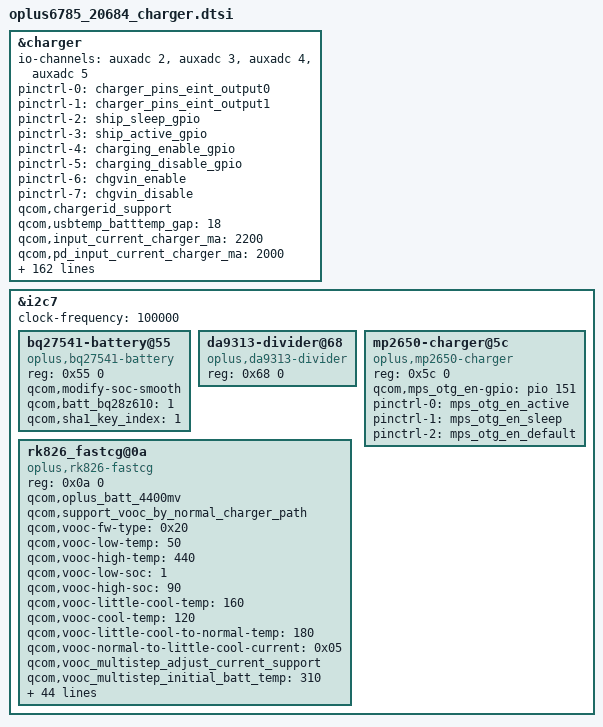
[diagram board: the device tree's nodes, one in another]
&charger {
	io-channels = <&auxadc 2>,
		      <&auxadc 3>,
		      <&auxadc 4>,
		      <&auxadc 5>;
	io-channel-names = "thermistor-ch2_usb_ntc_l",
			   "thermistor-ch3_usb_ntc_r",
			   "thermistor-ch4_charger_ntc",
			   "thermistor-ch5_flashlight_ntc";

	pinctrl-names = "charger_gpio_as_output_low", "charger_gpio_as_output_high", "ship_sleep", "ship_active", "dischg_disable", "dischg_enable", "chgvin_enable", "chgvin_disable";
	pinctrl-0 = <&charger_pins_eint_output0>;
	pinctrl-1 = <&charger_pins_eint_output1>;
	pinctrl-2 = <&ship_sleep_gpio>;
	pinctrl-3 = <&ship_active_gpio>;
	pinctrl-4 = <&charging_enable_gpio>;
	pinctrl-5 = <&charging_disable_gpio>;
	//pinctrl-5 = <&shortc_active_gpio>;
	pinctrl-6 = <&chgvin_enable>;
	pinctrl-7 = <&chgvin_disable>;
	//qcom,hv_flashled_support;
	//for oplus chg framework:
	qcom,chargerid_support;
	qcom,usbtemp_batttemp_gap = <18>;
	qcom,input_current_charger_ma = <2200>;
	qcom,pd_input_current_charger_ma = <2000>;
	qcom,qc_input_current_charger_ma = <2000>;
	qcom,input_current_usb_ma = <500>;
	qcom,input_current_cdp_ma = <1500>;
	qcom,input_current_led_ma = <1200>;
	qcom,input_current_led_ma_forcmcc = <500>;
	qcom,input_current_camera_ma = <2000>;
	qcom,input_current_calling_ma = <1500>;
	qcom,input_current_led_ma_high = <500>;
	qcom,input_current_led_ma_limit_high = <1200>;
	qcom,input_current_led_ma_warm = <1500>;
	qcom,input_current_led_ma_normal = <2000>;

	qcom,led_warm_bat_decidegc = <350>;
	qcom,led_limit_high_bat_decidegc = <370>;

	qcom,input_current_vooc_led_ma_high = <1200>;
	qcom,input_current_vooc_led_ma_warm = <1800>;
	qcom,input_current_vooc_led_ma_normal = <3600>;
	qcom,input_current_vooc_ma_normal = <3600>;
	qcom,vooc_temp_bat_normal_decidegc = <350>;
	qcom,input_current_vooc_ma_warm = <3200>;
	qcom,vooc_temp_bat_warm_decidegc = <370>;
	qcom,input_current_vooc_ma_high = <2200>;
	qcom,led_high_bat_decidegc = <440>;
	qcom,vooc_temp_bat_hot_decidegc = <440>;

	qcom,charger_current_vooc_ma_normal = <1800>;

	qcom,overtemp_bat_decidegc = <350>;
	qcom,iterm_disabled = <0>;
	sw_full_count = <25>;
	qcom,iterm_ma = <115>;
	qcom,recharge-mv = <105>;

	qcom,batt_capacity_mah = <4500>; /*typical capacity*/
	//qcom,batt_capacity_mah = <3900>; /*rated capacity*/

	qcom,removed_bat_decidegc = <190>;  /* < -19C */

	qcom,cold_bat_decidegc = <20>;  /* -3C ~ 0C */
	qcom,temp_cold_vfloat_mv = <3980>;
	qcom,temp_cold_fastchg_current_ma = <300>;

	qcom,little_cold_bat_decidegc = <0>;	/* 0C ~ 5C */
	qcom,temp_little_cold_vfloat_mv = <4435>;
	qcom,temp_little_cold_fastchg_current_ma_high = <950>;
	qcom,temp_little_cold_fastchg_current_ma_low = <950>;
	qcom,temp_little_cold_fastchg_current_ma = <950>;
	qcom,pd_temp_little_cold_fastchg_current_ma_high = <2000>;
	qcom,pd_temp_little_cold_fastchg_current_ma_low = <1400>;
	qcom,qc_temp_little_cold_fastchg_current_ma_high = <2000>;
	qcom,qc_temp_little_cold_fastchg_current_ma_low = <1400>;

	qcom,cool_bat_decidegc = <50>;	/* 5C ~ 12C */
	qcom,temp_cool_vfloat_mv = <4435>;
	qcom,temp_cool_fastchg_current_ma_high = <1000>;
	qcom,temp_cool_fastchg_current_ma_low = <1100>;
	qcom,pd_temp_cool_fastchg_current_ma_high = <2000>;
	qcom,qc_temp_cool_fastchg_current_ma_high = <2000>;
	qcom,qc_temp_cool_fastchg_current_ma_low = <2000>;

	qcom,little_cool_bat_decidegc = <120>;	/* 12C ~ 16C */
	qcom,temp_little_cool_vfloat_mv = <4435>;
	qcom,temp_little_cool_fastchg_current_ma = <1000>;
	qcom,pd_temp_little_cool_fastchg_current_ma = <2000>;
	qcom,qc_temp_little_cool_fastchg_current_ma = <2000>;

	qcom,normal_bat_decidegc = <160>;	/* 16C ~ 45C */
	qcom,temp_normal_fastchg_current_ma = <1000>;
	qcom,temp_normal_vfloat_mv = <4435>;
	qcom,pd_temp_normal_fastchg_current_ma = <2000>;
	qcom,qc_temp_normal_fastchg_current_ma = <2000>;

	qcom,warm_bat_decidegc = <440>;		/* 45C ~ 53C */ /*8pin Bat Vooc project need add 3 degree C*/

	qcom,temp_warm_vfloat_mv = <4120>;
	qcom,temp_warm_fastchg_current_ma = <550>;
	qcom,pd_temp_warm_fastchg_current_ma = <600>;
	qcom,qc_temp_warm_fastchg_current_ma = <600>;
	qcom,temp_warm_fastchg_current_ma_led_on = <250>;

	qcom,hot_bat_decidegc = <530>;  /* > 53C */

	qcom,non_standard_vfloat_mv = <3980>;
	qcom,non_standard_fastchg_current_ma = <512>;

	qcom,short_c_bat_cv_mv = <4330>;
	qcom,short_c_bat_vfloat_mv = <3800>;
	qcom,short_c_bat_fastchg_current_ma = <512>;
	qcom,short_c_bat_vfloat_sw_limit = <3750>;

	qcom,cold_vfloat_sw_limit = <3930>;
	qcom,little_cold_vfloat_sw_limit = <4385>;
	qcom,cool_vfloat_sw_limit = <4385>;
	qcom,little_cool_vfloat_sw_limit = <4385>;
	qcom,normal_vfloat_sw_limit = <4385>;
	qcom,warm_vfloat_sw_limit = <4080>;
	qcom,non_standard_vfloat_sw_limit = <3930>;

	qcom,max_chg_time_sec = <60624>;
	qcom,charger_hv_thr = <9900>;
	qcom,charger_recv_thr = <9500>;
	qcom,charger_lv_thr = <3400>;
	qcom,vbatt_full_thr = <4400>;
	qcom,vbatt_hv_thr = <4550>;

	qcom,vfloat_step_mv = <8>;
	qcom,non_standard_vfloat_over_sw_limit = <3980>;
	qcom,cold_vfloat_over_sw_limit = <3980>;
	qcom,little_cold_vfloat_over_sw_limit = <4440>;
	qcom,cool_vfloat_over_sw_limit = <4440>;
	qcom,little_cool_vfloat_over_sw_limit = <4440>;
	qcom,normal_vfloat_over_sw_limit = <4440>;
	qcom,warm_vfloat_over_sw_limit = <4135>;

	qcom,vbatt_power_off = <3300>;
	qcom,vbatt_soc_1 = <3310>;
	qcom,vooc_project = <3>;
	qcom,vbatt_num = <2>;
	qcom,new_ui_warning_support;
	qcom,ffc_support;
	qcom,dual_ffc;
	recharge_after_full;

	qcom,normal_vterm_hw_inc = <18>;
	qcom,non_normal_vterm_hw_inc = <18>;

	qcom,ff1_normal_fastchg_ma = <550>;
	qcom,ff1_warm_fastchg_ma = <550>;
	qcom,ffc2_normal_fastchg_ma = <350>;/*12C~35c*/
	qcom,ffc2_temp_warm_decidegc = <350>;
	qcom,ffc2_warm_fastchg_ma = <350>;/*35C~40c*/
	qcom,ffc2_temp_high_decidegc = <400>;
	qcom,ffc2_temp_low_decidegc = <120>;
	qcom,ff1_exit_step_ma = <150>;
	qcom,ff1_warm_exit_step_ma = <150>;
	qcom,ffc2_exit_step_ma = <150>;
	qcom,ffc2_warm_exit_step_ma = <150>;

	qcom,ffc_normal_vfloat_sw_limit = <4455>;
	qcom,ffc_temp_normal_vfloat_mv = <4500>;
	qcom,ffc_normal_vfloat_over_sw_limit = <4500>;
	qcom,ffc_warm_vfloat_sw_limit = <4450>;
	qcom,ffc_temp_warm_vfloat_mv = <4500>;
	qcom,ffc_warm_vfloat_over_sw_limit = <4500>;

	qcom,ffc2_normal_vfloat_sw_limit = <4445>;
	qcom,ffc2_temp_normal_vfloat_mv = <4500>;
	qcom,ffc2_normal_vfloat_over_sw_limit = <4500>;
	qcom,ffc2_warm_vfloat_sw_limit = <4440>;
	qcom,ffc2_temp_warm_vfloat_mv = <4500>;
	qcom,ffc2_warm_vfloat_over_sw_limit = <4500>;

	qcom,default_iterm_ma = <115>;
	qcom,default_temp_normal_fastchg_current_ma = <2200>;
	qcom,default_normal_vfloat_sw_limit = <4385>;
	qcom,default_temp_normal_vfloat_mv = <4435>;
	qcom,default_normal_vfloat_over_sw_limit = <4440>;
	qcom,default_temp_little_cool_fastchg_current_ma = <1100>;
	qcom,default_little_cool_vfloat_sw_limit = <4385>;
	qcom,default_temp_little_cool_vfloat_mv = <4435>;
	qcom,default_little_cool_vfloat_over_sw_limit = <4445>;
	//qcom,suspend_after_full;
	qcom,check_batt_full_by_sw;
	qcom,external_gauge;
	qcom,chg_ctrl_by_calling;
	qcom,chg_ctrl_by_lcd;
	qcom,chg_ctrl_by_vooc;
	qcom,chg_ctrl_by_camera;
	qcom,sw_vfloat_over_protect_enable;

	//for PD9V or QC9V
	qcom,vbatt_pdqc_to_5v_thr = <4100>;
	qcom,vbatt_pdqc_to_9v_thr = <4000>;

	//GPIO config:
	qcom,chargerid_switch-gpio = <&pio 195 0x00>;
	qcom,ship-gpio = <&pio 26 0x00>;
	qcom,dischg-gpio = <&pio 13 0x00>;
	//qcom,shortc-gpio = <&pio 148 0x00>;
	qcom,chgvin = <&pio 127 0x00>;
};

&i2c7 {
	status = "okay";
	clock-frequency = <100000>;
	bq27541-battery@55 {
		status = "okay";
		compatible = "oplus,bq27541-battery";
		reg = <0x55 0>;
		qcom,modify-soc-smooth;
		qcom,batt_bq28z610 = <1>;
		qcom,sha1_key_index = <1>;
		//qcom,bq28z610_need_balancing;
	};

	da9313-divider@68 {
		status = "okay";
		compatible = "oplus,da9313-divider";
		reg = <0x68 0>;
	};

	mp2650-charger@5c {
		status = "okay";
		compatible = "oplus,mp2650-charger";
		reg = <0x5c 0>;

		qcom,mps_otg_en-gpio = <&pio 151 0x00>;
		pinctrl-names = "mps_otg_en_active", "mps_otg_en_sleep", "mps_otg_en_default";
		pinctrl-0 = <&mps_otg_en_active>;
		pinctrl-1 = <&mps_otg_en_sleep>;
		pinctrl-2 = <&mps_otg_en_default>;
	};

	rk826_fastcg@0a{
		status = "okay";
		compatible = "oplus,rk826-fastcg";
		reg = <0x0a 0>;
		qcom,oplus_batt_4400mv;
		qcom,support_vooc_by_normal_charger_path;
		//qcom,vooc_fw_update_newmethod;
		qcom,vooc-fw-type = <0x20>;
		//qcom,vooc_reply_mcu_bits = <7>;
		qcom,vooc-low-temp = <50>;
		qcom,vooc-high-temp = <440>;
		qcom,vooc-low-soc = <1>;
		qcom,vooc-high-soc = <90>;
		qcom,vooc-little-cool-temp = <160>;
		qcom,vooc-cool-temp = <120>;
		qcom,vooc-little-cool-to-normal-temp = <180>;
		qcom,vooc-normal-to-little-cool-current = <0x05>;//5A

		qcom,vooc_multistep_adjust_current_support;
		qcom,vooc_multistep_initial_batt_temp = <310>;
		qcom,vooc_strategy_normal_current = <0x06>;
		qcom,vooc_batt_over_high_temp = <440>;
		qcom,vooc_batt_over_low_temp = <45>;
		qcom,vooc_over_high_or_low_current = <0x0>;

		qcom,vooc_strategy1_batt_high_temp0 = <425>;
		qcom,vooc_strategy1_batt_high_temp1 = <430>;
		qcom,vooc_strategy1_batt_high_temp2 = <435>;
		qcom,vooc_strategy1_batt_low_temp2 = <420>;
		qcom,vooc_strategy1_batt_low_temp1 = <415>;
		qcom,vooc_strategy1_batt_low_temp0 = <400>;

		qcom,vooc_strategy1_high_current0 = <0x04>;//4A
		qcom,vooc_strategy1_high_current1 = <0x03>;//3A
		qcom,vooc_strategy1_high_current2 = <0x02>;//2A
		qcom,vooc_strategy1_low_current2 = <0x03>;//3A
		qcom,vooc_strategy1_low_current1 = <0x04>;//4A
		qcom,vooc_strategy1_low_current0 = <0x04>;//4A

		qcom,vooc_strategy2_batt_up_temp1 = <375>;
		qcom,vooc_strategy2_batt_up_down_temp2 = <380>;
		qcom,vooc_strategy2_batt_up_temp3 = <390>;
		qcom,vooc_strategy2_batt_up_down_temp4 = <400>;
		qcom,vooc_strategy2_batt_up_temp5 = <410>;
		qcom,vooc_strategy2_batt_up_temp6 = <415>;
		qcom,vooc_strategy2_high0_current = <0x05>;
		qcom,vooc_strategy2_high1_current = <0x04>;
		qcom,vooc_strategy2_high2_current = <0x03>;
		qcom,vooc_strategy2_high3_current = <0x02>;

		qcom,vooc_current_lvl = <1000
									1500
									2000
									2500
									3000
									3500
									4000
									4500
									5000
									5500
									6000
									6500
									7000
									7500
									8000
									8500
									9000
									9500
									10000
									10500
									11000
									11500
									12000
									12500>;

		pinctrl-names = "switch1_act_switch2_act", "switch1_sleep_switch2_sleep",
						"switch1_act_switch3_act", "switch1_sleep_switch3_sleep",
						"switch1_act_switch2_sleep", "switch1_sleep_switch2_act",
						"clock_active","clock_sleep",
						"data_active","data_sleep",
						"reset_active","reset_sleep";
						//"charging_switch1_ctr1_active","charging_switch1_ctr1_sleep",
						//"vooc_asic_id_active","vooc_asic_id_sleep";
		pinctrl-0 = <&charging_switch1_active>;
		pinctrl-1 = <&charging_switch1_sleep>;
		pinctrl-2 = <&charging_switch1_active>;
		pinctrl-3 = <&charging_switch1_sleep>;
		pinctrl-4 = <&charging_switch1_active>;
		pinctrl-5 = <&charging_switch1_sleep>;
		pinctrl-6 = <&charging_clock_active>;
		pinctrl-7 = <&charging_clock_sleep>;
		pinctrl-8 = <&charging_data_active>;
		pinctrl-9 = <&charging_data_sleep>;
		pinctrl-10 = <&charging_reset_active>;
		pinctrl-11 = <&charging_reset_sleep>;
		//pinctrl-12 = <&charging_switch1_ctr1_active>;
		//pinctrl-13 = <&charging_switch1_ctr1_sleep>;
		//pinctrl-14 = <&vooc_asic_id_active>;
		//pinctrl-15 = <&vooc_asic_id_sleep>;

		qcom,charging_switch1-gpio 		= <&pio 34 0x00>;
		//qcom,charging_switch1_ctr1-gpio 	= <&pio 163 0x00>;	//empty
		//qcom,charging_switch2-gpio 		= <&tlmm 34 0x00>;
		//qcom,charging_switch3-gpio 		= <&tlmm 34 0x00>;

		qcom,charging_reset-gpio 			= <&pio 14 0x00>;
		qcom,charging_clock-gpio 			= <&pio 68 0x00>;
		qcom,charging_data-gpio 			= <&pio 67 0x00>;
		//qcom,vooc_asic_id-gpio				= <&pio 148 0x00>;
	};
};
